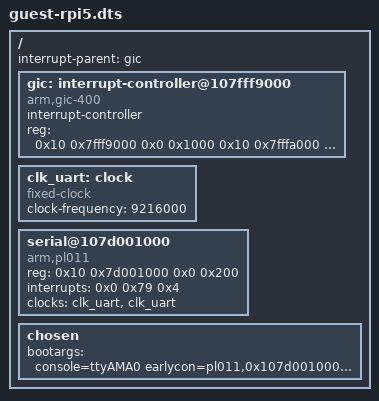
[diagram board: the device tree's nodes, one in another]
/**
 * @file bsp/rpi5/dts/guest-rpi5.dts
 * @brief Guest device tree for Raspberry Pi 5 (BCM2712).
 * @ingroup bsp
 */

/dts-v1/;
/include/ "guest-base.dtsi"

/ {
	interrupt-parent = <&gic>;

	gic: interrupt-controller@107fff9000 {
		compatible = "arm,gic-400";
		#interrupt-cells = <3>;
		#address-cells = <0>;
		interrupt-controller;
		// GICD and the CPU interface only. GICH and GICV are the
		// hypervisor's own frames: a guest that reaches GICH programs the
		// list registers that inject its own interrupts. Stage 2 maps only
		// what this node declares, so declaring them would be both a lie
		// and a request to hand them over.
		reg = <0x10 0x7fff9000 0x0 0x1000
		       0x10 0x7fffa000 0x0 0x2000>;
	};

	clk_uart: clock {
		compatible = "fixed-clock";
		#clock-cells = <0>;
		clock-frequency = <9216000>;
	};

	serial@107d001000 {
		compatible = "arm,pl011", "arm,primecell";
		reg = <0x10 0x7d001000 0x0 0x200>;
		interrupts = <0x0 0x79 0x4>;
		clocks = <&clk_uart &clk_uart>;
		clock-names = "uartclk", "apb_pclk";
	};

	chosen {
		bootargs = "console=ttyAMA0 earlycon=pl011,0x107d001000 rdinit=/sbin/init";
	};
};
